# LPC15xx register map
File version: 0.7
CPU: CM3 r2p1, little endian, no MPU, no FPU, 3 interrupt priority bits
Registers are 32-bit, read-write, reset 0x0 unless marked. A register's access mark holds for its fields unless they carry their own. Offsets are from the block's base; [hi:lo] are bit positions; {n}, {i} and the like mark numbered series.

## PMU — Power Management Unit (PMU)
Base 0x4003C000
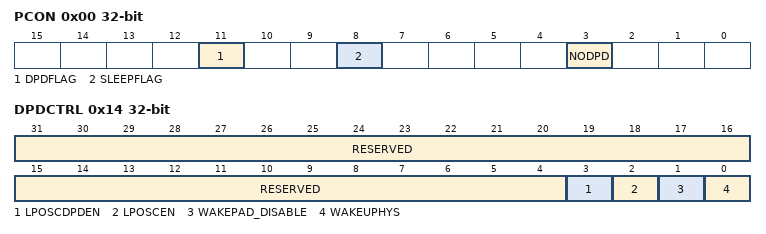
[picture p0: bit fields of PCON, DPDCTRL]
0x00 PCON — Power control register
  [11] DPDFLAG — Deep power-down flag
    0=READ_DEEP_POWER_DOW (Read: Deep power-down mode not entered. Write: No effect.); 1=READ_DEEP_POWER_DOW (Read: Deep power-down mode entered. Write: Clear the Deep power-down flag.)
  [8] SLEEPFLAG — Sleep mode flag
    0=READ_NO_POWER_DOWN (Read: No power-down mode entered. The part is in Active mode. Write: No effect.); 1=SLEEP_DEEP_SLEEP (Read: Sleep/Deep-sleep or Deep power-down mode entered. Write: Writing a 1 clears the SLEEPFLAG bit to 0.)
  [3] NODPD — A 1 in this bit prevents entry to Deep power-down mode. This bit is cleared by power-on reset.
{0x4+4i} GPREG{i} (i=0..3) — General purpose register 0
  [31:0] GPDATA — Data retained during Deep power-down mode.
0x14 DPDCTRL — Deep power-down control register
  [31:4] RESERVED — Data retained during Deep power-down mode.
  [3] LPOSCDPDEN — Enable the low-power oscillator in Deep power-down mode. Setting this bit causes the low-power oscillator to remain running during Deep power-down mode provided that bit 2 in this register is set as well. You must set this bit for the self wake-up timer to be able to wake up the part from Deep power-down mode. Do not set this bit unless you use the self wake-up timer to wake up from Deep power-down mode.
    0=DISABLED; 1=ENABLED
  [2] LPOSCEN — Enable the low-power oscillator for use with the 10 kHz self wake-up timer clock. You must set this bit if the CLKSEL bit in the self wake-up timer CTRL bit is set. Do not enable the low-power oscillator if the self wake-up timer is clocked by the divided IRC.
    0=DISABLED; 1=ENABLED
  [1] WAKEPAD_DISABLE — WAKEUP pin disable. Setting this bit disables the wake-up pin, so it can be used for other purposes. Never set this bit if you intend to use a pin to wake up the part from Deep power-down mode. You can only disable the wake-up pin if the self wake-up timer is enabled and configured. Setting this bit is not necessary if Deep power-down mode is not used.
    0=ENABLED (Enabled. The wake-up function is enabled on pin PIO0_4.); 1=DISABLED (Disabled. Setting this bit disables the wake-up function on pin PIO0_4.)
  [0] WAKEUPHYS — WAKEUP pin hysteresis enable
    0=DISABLED (Disabled. Hysteresis for WAKEUP pin disabled.); 1=ENABLED (Enabled. Hysteresis for WAKEUP pin enabled.)

## MRT — Multi-Rate Timer (MRT)
Base 0x400A0000
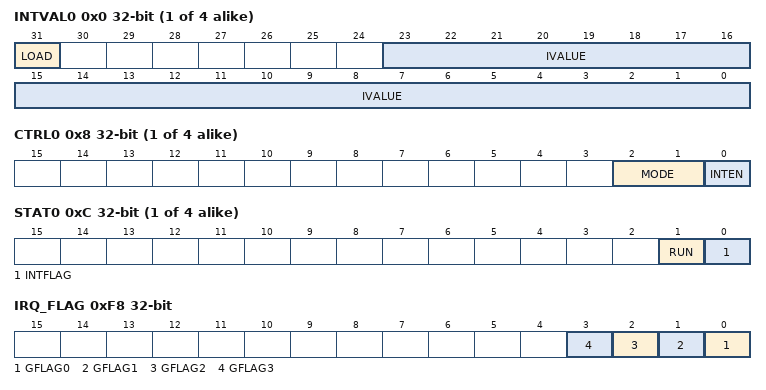
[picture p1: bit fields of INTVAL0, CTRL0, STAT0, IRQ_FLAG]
{0x0+0x10*i} INTVAL{i} (i=0..3) — MRT0 Time interval value register. This value is loaded into the TIMER0 register.
  [31] LOAD — Determines how the timer interval value IVALUE -1 is loaded into the TIMERn register. This bit is write-only. Reading this bit always returns 0.
    0=NO_FORCE_LOAD (No force load. The load from the INTVALn register to the TIMERn register is processed at the end of the time interval if the repeat mode is selected.); 1=FORCE_LOAD (Force load. The INTVALn interval value IVALUE -1 is immediately loaded into the TIMERn register while TIMERn is running.)
  [23:0] IVALUE — Time interval load value. This value is loaded into the TIMERn register and the MRTn starts counting down from IVALUE -1. If the timer is idle, writing a non-zero value to this bit field starts the timer immediately. If the timer is running, writing a zero to this bit field does the following: If LOAD = 1, the timer stops immediately. If LOAD = 0, the timer stops at the end of the time interval.
{0x4+0x10*i} TIMER{i} (i=0..3) ro reset 0xFFFFFF — MRT0 Timer register. This register reads the value of the down-counter.
  [23:0] VALUE — Holds the current timer value of the down-counter. The initial value of the TIMERn register is loaded as IVALUE - 1 from the INTVALn register either at the end of the time interval or immediately in the following cases: INTVALn register is updated in the idle state. INTVALn register is updated with LOAD = 1. When the timer is in idle state, reading this bit fields returns -1 (0x00FF FFFF).
{0x8+0x10*i} CTRL{i} (i=0..3) — MRT0 Control register. This register controls the MRT0 modes.
  [2:1] MODE — Selects timer mode.
    0=REPEAT_INTERRUPT_MOD (Repeat interrupt mode.); 1=ONE_SHOT_INTERRUPT_M (One-shot interrupt mode.)
  [0] INTEN — Enable the TIMERn interrupt.
    0=DISABLE; 1=ENABLE
{0xC+0x10*i} STAT{i} (i=0..3) — MRT0 Status register.
  [1] RUN — Indicates the state of TIMERn. This bit is read-only.
    0=IDLE_STATE (Idle state. TIMERn is stopped.); 1=RUNNING (Running. TIMERn is running.)
  [0] INTFLAG — Monitors the interrupt flag.
    0=NO_PENDING_INTERRUPT (No pending interrupt. Writing a zero is equivalent to no operation.); 1=PENDING_INTERRUPT (Pending interrupt. The interrupt is pending because TIMERn has reached the end of the time interval. If the INTEN bit in the CONTROLn is also set to 1, the interrupt for timer channel n and the global interrupt are raised. Writing a 1 to this bit clears the interrupt request.)
0xF4 IDLE_CH ro — Idle channel register. This register returns the number of the first idle channel.
  [7:4] CHAN — Idle channel. Reading the CHAN bits, returns the lowest idle timer channel. If all timer channels are running, CHAN = 4. To make sure that all outstanding interrupt requests have been serviced, a channel is considered idle only when both the corresponding RUN bit and the interrupt flag are zero in the STATUS register.
0xF8 IRQ_FLAG — Global interrupt flag register
  [n] GFLAG{n} (n=0..3) — Monitors the interrupt flag of TIMER{n}.
    0=NO_PENDING_INTERRUPT (No pending interrupt. Writing a zero is equivalent to no operation.); 1=PENDING_INTERRUPT (Pending interrupt. The interrupt is pending because TIMER{n} has reached the end of the time interval. If the INTEN bit in the CONTROL{n} register is also set to 1, the interrupt for timer channel {n} and the global interrupt are raised. Writing a 1 to this bit clears the interrupt request.)
